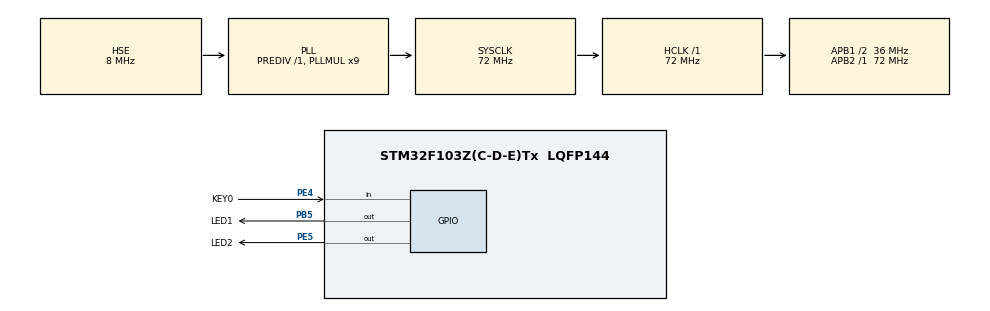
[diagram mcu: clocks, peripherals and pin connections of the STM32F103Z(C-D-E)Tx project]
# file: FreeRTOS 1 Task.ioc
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FREERTOS.Tasks01=myLED1Task,0,128,LED1Task,Default,NULL,Dynamic,NULL,NULL;myLED2Task,0,128,LED2Task,Default,NULL,Dynamic,NULL,NULL;myKEY,0,128,KEYTask,Default,NULL,Dynamic,NULL,NULL
FREERTOS.configTOTAL_HEAP_SIZE=4082
FREERTOS.configUSE_TIMERS=0
Mcu.Family=STM32F1
Mcu.Name=STM32F103Z(C-D-E)Tx
Mcu.Package=LQFP144
NVIC.PriorityGroup=NVIC_PRIORITYGROUP_4
NVIC.TIM1_UP_IRQn=true\:15\:0\:false\:false\:true\:false\:false\:true
NVIC.TimeBase=TIM1_UP_IRQn
NVIC.TimeBaseIP=TIM1
OSC_IN.Mode=HSE-External-Oscillator
OSC_IN.Signal=RCC_OSC_IN
OSC_OUT.Mode=HSE-External-Oscillator
OSC_OUT.Signal=RCC_OSC_OUT
PA13.Mode=Serial_Wire
PA13.Signal=SYS_JTMS-SWDIO
PA14.Mode=Serial_Wire
PA14.Signal=SYS_JTCK-SWCLK
PB5.GPIO_Label=LED1
PB5.Signal=GPIO_Output
PE4.GPIO_Label=KEY0
PE4.GPIO_PuPd=GPIO_PULLUP
PE4.Signal=GPIO_Input
PE5.GPIO_Label=LED2
PE5.Signal=GPIO_Output
ProjectManager.HeapSize=0x200
ProjectManager.StackSize=0x400
ProjectManager.TargetToolchain=MDK-ARM V5.32
RCC.AHBFreq_Value=72000000
RCC.APB1CLKDivider=RCC_HCLK_DIV2
RCC.APB1Freq_Value=36000000
RCC.APB1TimFreq_Value=72000000
RCC.APB2Freq_Value=72000000
RCC.APB2TimFreq_Value=72000000
RCC.HCLKFreq_Value=72000000
RCC.PLLMUL=RCC_PLL_MUL9
RCC.PLLSourceVirtual=RCC_PLLSOURCE_HSE
RCC.SYSCLKFreq_VALUE=72000000
RCC.SYSCLKSource=RCC_SYSCLKSOURCE_PLLCLK
RCC.USBFreq_Value=72000000
VP_FREERTOS_VS_CMSIS_V1.Mode=CMSIS_V1
VP_SYS_VS_tim1.Mode=TIM1
board=custom

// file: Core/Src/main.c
/* USER CODE BEGIN Header */
/**
  ******************************************************************************
  * @file           : main.c
  * @brief          : Main program body
  ******************************************************************************
  * @attention
  *
  * Copyright (c) 2023 STMicroelectronics.
  * All rights reserved.
  *
  * This software is licensed under terms that can be found in the LICENSE file
  * in the root directory of this software component.
  * If no LICENSE file comes with this software, it is provided AS-IS.
  *
  ******************************************************************************
  */
/* USER CODE END Header */
#include "main.h"
#include "cmsis_os.h"
#include "gpio.h"

void SystemClock_Config(void);
void MX_FREERTOS_Init(void);

int main(void)
{

  /* MCU Configuration--------------------------------------------------------*/

  /* Reset of all peripherals, Initializes the Flash interface and the Systick. */
  HAL_Init();

  /* Configure the system clock */
  SystemClock_Config();

  /* Initialize all configured peripherals */
  MX_GPIO_Init();

  /* Call init function for freertos objects (in freertos.c) */
  MX_FREERTOS_Init();
  /* Start scheduler */
  osKernelStart();

  /* We should never get here as control is now taken by the scheduler */
  /* Infinite loop */
  while (1)
  {

  }
}

void SystemClock_Config(void)
{
  RCC_OscInitTypeDef RCC_OscInitStruct = {0};
  RCC_ClkInitTypeDef RCC_ClkInitStruct = {0};

  /** Initializes the RCC Oscillators according to the specified parameters
  * in the RCC_OscInitTypeDef structure.
  */
  RCC_OscInitStruct.OscillatorType = RCC_OSCILLATORTYPE_HSE;
  RCC_OscInitStruct.HSEState = RCC_HSE_ON;
  RCC_OscInitStruct.HSEPredivValue = RCC_HSE_PREDIV_DIV1;
  RCC_OscInitStruct.HSIState = RCC_HSI_ON;
  RCC_OscInitStruct.PLL.PLLState = RCC_PLL_ON;
  RCC_OscInitStruct.PLL.PLLSource = RCC_PLLSOURCE_HSE;
  RCC_OscInitStruct.PLL.PLLMUL = RCC_PLL_MUL9;
  if (HAL_RCC_OscConfig(&RCC_OscInitStruct) != HAL_OK)
  {
    Error_Handler();
  }
  /** Initializes the CPU, AHB and APB buses clocks
  */
  RCC_ClkInitStruct.ClockType = RCC_CLOCKTYPE_HCLK|RCC_CLOCKTYPE_SYSCLK
                              |RCC_CLOCKTYPE_PCLK1|RCC_CLOCKTYPE_PCLK2;
  RCC_ClkInitStruct.SYSCLKSource = RCC_SYSCLKSOURCE_PLLCLK;
  RCC_ClkInitStruct.AHBCLKDivider = RCC_SYSCLK_DIV1;
  RCC_ClkInitStruct.APB1CLKDivider = RCC_HCLK_DIV2;
  RCC_ClkInitStruct.APB2CLKDivider = RCC_HCLK_DIV1;

  if (HAL_RCC_ClockConfig(&RCC_ClkInitStruct, FLASH_LATENCY_2) != HAL_OK)
  {
    Error_Handler();
  }
}

void HAL_TIM_PeriodElapsedCallback(TIM_HandleTypeDef *htim)
{
  if (htim->Instance == TIM1) {
    HAL_IncTick();
  }
}

void Error_Handler(void)
{
  __disable_irq();
  while (1)
  {
  }
}

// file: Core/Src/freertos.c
/* USER CODE BEGIN Header */
/**
  ******************************************************************************
  * File Name          : freertos.c
  * Description        : Code for freertos applications
  ******************************************************************************
  * @attention
  *
  * Copyright (c) 2023 STMicroelectronics.
  * All rights reserved.
  *
  * This software is licensed under terms that can be found in the LICENSE file
  * in the root directory of this software component.
  * If no LICENSE file comes with this software, it is provided AS-IS.
  *
  ******************************************************************************
  */
/* USER CODE END Header */

#include "FreeRTOS.h"
#include "task.h"
#include "main.h"
#include "cmsis_os.h"

osThreadId myLED1TaskHandle;
osThreadId myLED2TaskHandle;
osThreadId myKEYHandle;

void LED1Task(void const * argument);
void LED2Task(void const * argument);
void KEYTask(void const * argument);

void MX_FREERTOS_Init(void); /* (MISRA C 2004 rule 8.1) */

/* GetIdleTaskMemory prototype (linked to static allocation support) */
void vApplicationGetIdleTaskMemory( StaticTask_t **ppxIdleTaskTCBBuffer, StackType_t **ppxIdleTaskStackBuffer, uint32_t *pulIdleTaskStackSize );

/* USER CODE BEGIN GET_IDLE_TASK_MEMORY */
static StaticTask_t xIdleTaskTCBBuffer;
static StackType_t xIdleStack[configMINIMAL_STACK_SIZE];

void vApplicationGetIdleTaskMemory( StaticTask_t **ppxIdleTaskTCBBuffer, StackType_t **ppxIdleTaskStackBuffer, uint32_t *pulIdleTaskStackSize )
{
  *ppxIdleTaskTCBBuffer = &xIdleTaskTCBBuffer;
  *ppxIdleTaskStackBuffer = &xIdleStack[0];
  *pulIdleTaskStackSize = configMINIMAL_STACK_SIZE;
  /* place for user code */
}
/* USER CODE END GET_IDLE_TASK_MEMORY */

void MX_FREERTOS_Init(void) {

  /* Create the thread(s) */
  /* definition and creation of myLED1Task */
  osThreadDef(myLED1Task, LED1Task, osPriorityNormal, 0, 128);
  myLED1TaskHandle = osThreadCreate(osThread(myLED1Task), NULL);

  /* definition and creation of myLED2Task */
  osThreadDef(myLED2Task, LED2Task, osPriorityNormal, 0, 128);
  myLED2TaskHandle = osThreadCreate(osThread(myLED2Task), NULL);

  /* definition and creation of myKEY */
  osThreadDef(myKEY, KEYTask, osPriorityNormal, 0, 128);
  myKEYHandle = osThreadCreate(osThread(myKEY), NULL);

}

void LED1Task(void const * argument)
{
  /* USER CODE BEGIN LED1Task */
  /* Infinite loop */
	osThreadSuspend(NULL);
  for(;;)
  {

	  HAL_GPIO_TogglePin(LED1_GPIO_Port,LED1_Pin);
	  osDelay(300);
  }
  /* USER CODE END LED1Task */
}

void LED2Task(void const * argument)
{
  /* USER CODE BEGIN LED2Task */
  /* Infinite loop */
//	osThreadSuspend(NULL);
  for(;;)
  {
	  HAL_GPIO_TogglePin(LED2_GPIO_Port,LED2_Pin);
	  osDelay(300);
  }
  /* USER CODE END LED2Task */
}

void KEYTask(void const * argument)
{
  /* USER CODE BEGIN KEYTask */
  /* Infinite loop */
	static uint8_t flag=0;
  for(;;)
  {
    if(HAL_GPIO_ReadPin(KEY0_GPIO_Port,KEY0_Pin)==0&&flag==0)
    {
    osDelay(10);//延时检测按键按下情况，防止误判
    if(HAL_GPIO_ReadPin(KEY0_GPIO_Port,KEY0_Pin)==0&&flag==0)
    {
    osThreadResume(myLED1TaskHandle);
    flag=1;
    }
    while(HAL_GPIO_ReadPin(KEY0_GPIO_Port,KEY0_Pin)==0) //等待按键释放
    {
    osDelay(10);
    }
    }

    if(HAL_GPIO_ReadPin(KEY0_GPIO_Port,KEY0_Pin)==0&&flag==1)
    {
    osDelay(10); //延时检测按键按下情况，防止误判
    if(HAL_GPIO_ReadPin(KEY0_GPIO_Port,KEY0_Pin)==0&&flag==1)
    {
    osThreadSuspend(myLED1TaskHandle);
    flag=0;
    }
    while(HAL_GPIO_ReadPin(KEY0_GPIO_Port,KEY0_Pin)==0) //等待按键释放
    {
    osDelay(10);
    }
    }

    osDelay(1);

  }
  /* USER CODE END KEYTask */
}
